# R7KA8D2AD register map
Vendor: Renesas Electronics Corporation; Series: RA8; File version: 1.10.02
CPU: CM85 r0p2, little endian, MPU, FPU, VTOR, 4 interrupt priority bits, 96 interrupts
Registers are 32-bit, read-write, reset 0x0 unless marked. A register's access mark holds for its fields unless they carry their own. Offsets are from the block's base; [hi:lo] are bit positions.

## MIPI_PHY0 — PHY Controller Top
Base 0x40346C00
Same registers: MIPI_PHY0_NS 0x50346C00
0x00 DPHYREFCR reset 0x2F — D-PHY Reference Clock Setting Register
  [7:0] RFREQ — Reference Clock Frequency Setting
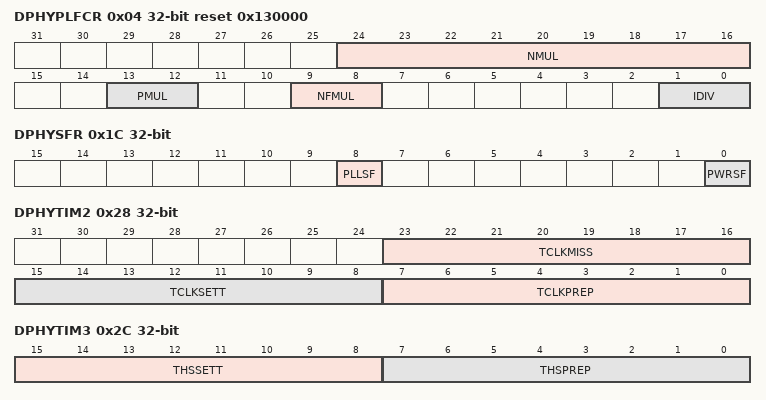
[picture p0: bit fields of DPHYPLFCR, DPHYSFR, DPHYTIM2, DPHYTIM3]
0x04 DPHYPLFCR reset 0x130000 — D-PHY PLL Frequency Control Register
  [24:16] NMUL — D-PHY PLL Frequency Multiplication Factor Select (Integer Part)
  [13:12] PMUL
    0=1; 1=1/2; 2=1/4; 3=1/8
  [9:8] NFMUL — D-PHY PLL Frequency Multiplication Factor Select (Fractional Part)
    0=0.00; 1=0.33; 2=0.66; 3=0.50
  [1:0] IDIV — D-PHY PLL Input Frequency Division Ratio Select
    0=1; 1=1/2; 2=1/3; 3=1/4
0x08 DPHYPLOCR reset 0x1 — D-PHY PLL Operation Control Register
  [0] PLLSTP — D-PHY PLL Operation Control
    0=Operate the PLL; 1=Stop the PLL
0x0C DPHYESCCR — D-PHY Escape Mode Clock Control Register
  [4:0] ESCDIV — Escape Mode Transfer Clock Division Ratio
0x10 DPHYPWRCR — D-PHY Power Supplying Control Register
  [0] PWRSEN — D-PHY Power Supplying Control
    0=Disable D-PHY LDO operation (stop supplying VDD_DPHY); 1=Enable D-PHY LDO operation (supply VDD_DPHY)
0x1C DPHYSFR ro — D-PHY Status Flag Register
  [8] PLLSF — D-PHY PLL Oscillation Stabilization Flag
    0=D-PHY PLL clock is stopped or is not yet stable; 1=D-PHY PLL clock is stable
  [0] PWRSF — D-PHY LDO Power-on Status Flag
    0=D-PHY LDO is stopped or starting up; 1=D-PHY LDO startup is completed (VDD_DPHY is stable)
0x20 DPHYOCR — D-PHY Operation Control Register
  [0] DPHYEN — D-PHY Operation Control
    0=Disable D-PHY operation; 1=Enable D-PHY operation
0x24 DPHYTIM1 — D-PHY Timing Control Register 1
  [18:0] TINIT — D-PHY T_INIT Parameter Setting
0x28 DPHYTIM2 — D-PHY Timing Control Register 2
  [23:16] TCLKMISS — D-PHY T_CLK_MISS Parameter Setting
  [15:8] TCLKSETT — D-PHY T_CLK_SETTLE Parameter Setting
  [7:0] TCLKPREP — D-PHY T_CLK_PREPARE Parameter Setting
0x2C DPHYTIM3 — D-PHY Timing Control Register 3
  [15:8] THSSETT — D-PHY T_THS_SETTLE Parameter Setting
  [7:0] THSPREP — D-PHY T_THS_PREPARE Parameter Setting
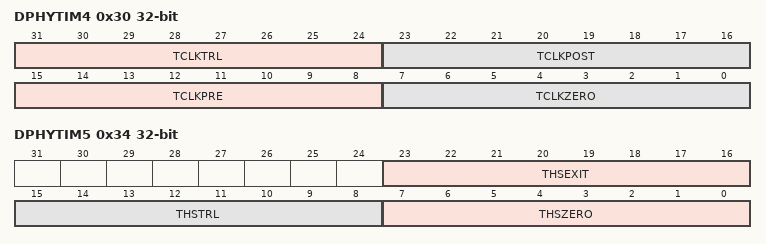
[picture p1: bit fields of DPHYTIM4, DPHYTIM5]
0x30 DPHYTIM4 — D-PHY Timing Control Register 4
  [31:24] TCLKTRL — D-PHY T_TCLK_TRAIL Parameter Setting
  [23:16] TCLKPOST — D-PHY T_TCLK_POST Parameter Setting
  [15:8] TCLKPRE — D-PHY T_TCLK_PRE Parameter Setting
  [7:0] TCLKZERO — D-PHY T_CLK_ZERO Parameter Setting
0x34 DPHYTIM5 — D-PHY Timing Control Register 5
  [23:16] THSEXIT — D-PHY T_THS_EXIT Parameter Setting
  [15:8] THSTRL — D-PHY T_THS_TRAIL Parameter Setting
  [7:0] THSZERO — D-PHY T_THS_ZERO Parameter Setting
0x38 DPHYTIM6 — D-PHY Timing Control Register 6
  [7:0] TLPX — D-PHY T_TLPX Parameter Setting
0x48 DPHYMDC — D-PHY Mode Control Register
  [0] MASTEREN — D-PHY Master/Slave Select
    0=Slave Mode (CSI-2 Version 3.0, D-PHY v2.1 CIL_SCNN,CIL_SFEN); 1=Master Mode (DSI-2 Version 1.1, D-PHY v2.1 CIL_MCNN,CIL_MFAA)

## ECCMB0
Base 0x4036F200
Same registers: ECCMB1 0x4036F300, ECCMB0_NS 0x5036F200, ECCMB1_NS 0x5036F300
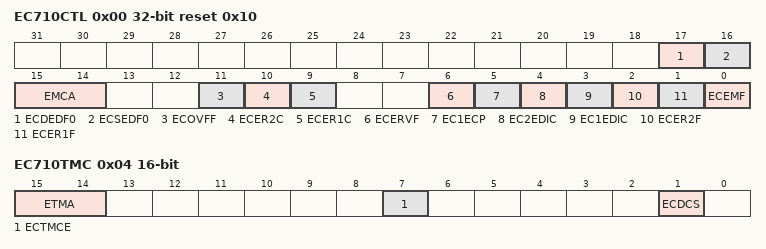
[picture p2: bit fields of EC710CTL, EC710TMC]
0x00 EC710CTL reset 0x10 — ECC Control Register
  [17] ECDEDF0 ro — ECC Dual Bit Error Address Detection Flag
    0=There is no bit error in EC710EAD0 after reset or clearing ECER2F bit; 1=Address captured in EC710EAD0 shows that 2-bit error occurred and captured
  [16] ECSEDF0 ro — ECC Single bit Error Address Detection Flag
    0=There is no bit error in EC710EAD0 after reset or clearing ECER1F bit; 1=Address captured in EC710EAD0 shows that 1-bit error occurred and captured
  [15:14] EMCA — Access Control to ECC Mode Select bit
  [11] ECOVFF ro — ECC Overflow Detection Flag
    0=No effect; 1=ECC overflow detection flag
  [10] ECER2C — 2-bit ECC Error Detection Flag Clear
    0=No effect; 1=Clear 2-bit ECC error detection flag
  [9] ECER1C — Accumulating ECC Error Detection and Correction Flag Clear
    0=No effect; 1=Clear accumulating ECC error detection and correction flag
  [6] ECERVF — ECC Error Judgment Enable Flag
    0=Error judgment disable; 1=Error judgment enable
  [5] EC1ECP — ECC 1-bit Error Correction Permission
    0=At 1-bit error detection, the error correction is executed; 1=At 1-bit error detection, the error correction is not executed
  [4] EC2EDIC — ECC 2-bit Error Detection Interrupt Control
    0=Disable 2-bit error detection interrupt request; 1=Enable 2-bit error detection interrupt request
  [3] EC1EDIC — ECC 1-bit Error Detection Interrupt Control
    0=Disable 1-bit error detection interrupt request; 1=Enable 1-bit error detection interrupt request
  [2] ECER2F ro — 2-bit ECC Error Detection Flag
    0=After clearing this bit, 2-bit error has not occurred; 1=2-bit error has occurred
  [1] ECER1F ro — ECC Error Detection and Correction Flag
    0=After clearing this bit, 1-bit error correction has not occurred; 1=1-bit error has occurred
  [0] ECEMF ro — ECC Error Message Flag
    0=There is no bit error in present RAM output data; 1=There is bit error in present RAM output data
0x04 EC710TMC 16-bit — ECC Test Mode Control Register
  [15:14] ETMA — ECC Test Mode Bit Access Control
  [7] ECTMCE — ECC Test Mode Control Enable
    0=The access to test mode register and bit is disabled; 1=The access to test mode register and bit is enabled
  [1] ECDCS — ECC Decode Input Select
    0=Input lower 32 bits of RAM output data to data area of decode circuit; 1=Input ECEDB31-0 in EC710TED register to data area of decode circuit
0x0C EC710TED — ECC Test Substitute Data Register
  [31:0] ECEDB — ECC Test Substitute Data
0x10 EC710EAD0 ro — ECC Error Address Register
  [9:0] ECEAD — ECC Error Address
